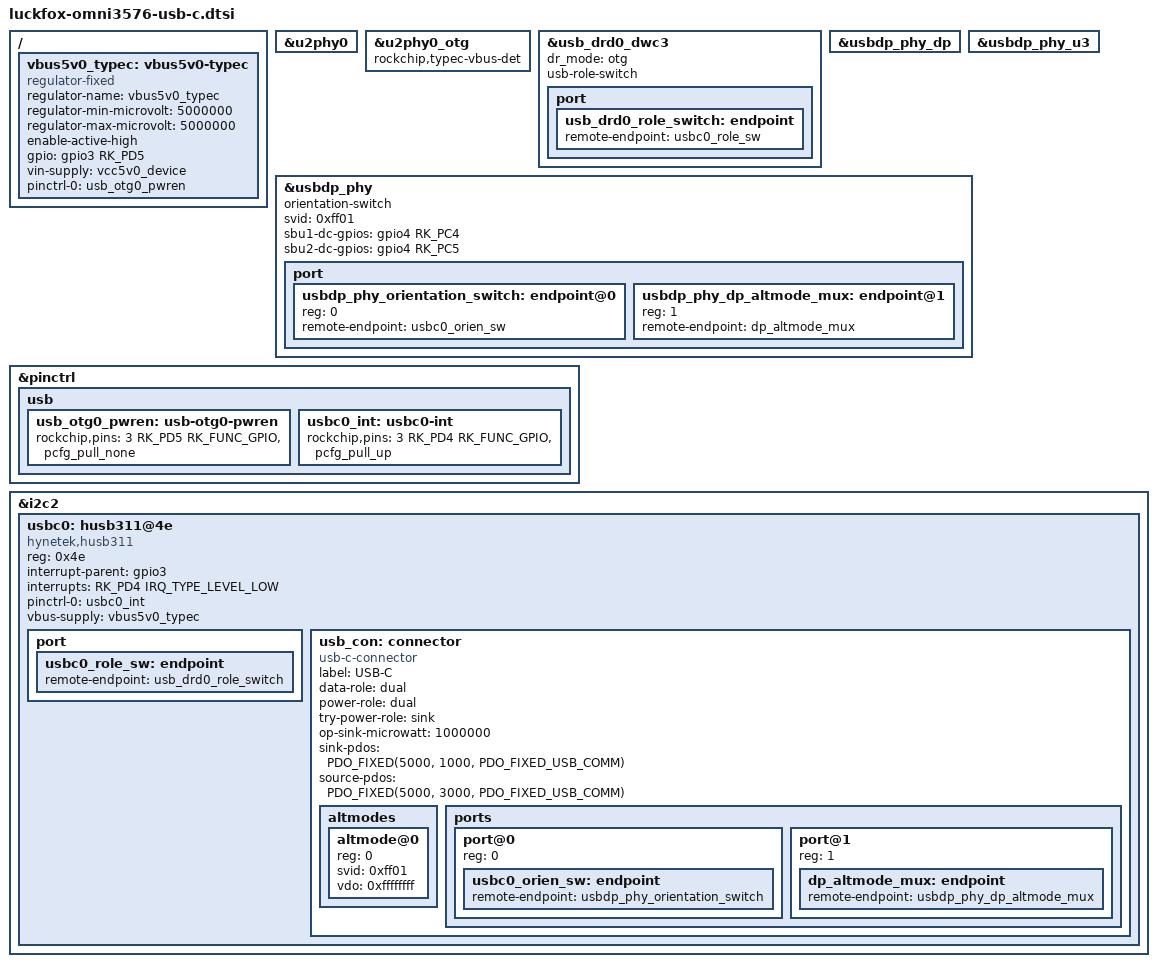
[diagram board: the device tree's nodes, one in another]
// SPDX-License-Identifier: (GPL-2.0+ OR MIT)
/*
 * Copyright (c) 2024 Luckfox Technology Co., Ltd.
 *
 */

#include <dt-bindings/usb/pd.h>
#include <dt-bindings/phy/phy.h>
// #include "luckfox-core3576.dtsi"
#include <dt-bindings/gpio/gpio.h>
#include <dt-bindings/display/rockchip_vop.h>

/ {
	vbus5v0_typec: vbus5v0-typec {
		compatible = "regulator-fixed";
		regulator-name = "vbus5v0_typec";
		regulator-min-microvolt = <5000000>;
		regulator-max-microvolt = <5000000>;
		enable-active-high;
		gpio = <&gpio3 RK_PD5 GPIO_ACTIVE_HIGH>;
		vin-supply = <&vcc5v0_device>;
		pinctrl-names = "default";
		pinctrl-0 = <&usb_otg0_pwren>;
	};
};

&u2phy0 {
	status = "okay";
};

&u2phy0_otg {
	rockchip,typec-vbus-det;
	status = "okay";
};

&usb_drd0_dwc3 {
	status = "okay";
	dr_mode = "otg";
	usb-role-switch;
	port {
		usb_drd0_role_switch: endpoint {
			remote-endpoint = <&usbc0_role_sw>;
		};
	};
};



&usbdp_phy_dp {
	status = "okay";
};
&usbdp_phy_u3 {
	status = "okay";
};
&usbdp_phy {
	status = "okay";
	orientation-switch;
	svid = <0xff01>;
	sbu1-dc-gpios = <&gpio4 RK_PC4 GPIO_ACTIVE_HIGH>;
	sbu2-dc-gpios = <&gpio4 RK_PC5 GPIO_ACTIVE_HIGH>;

	port {
		#address-cells = <1>;
		#size-cells = <0>;

		usbdp_phy_orientation_switch: endpoint@0 {
			reg = <0>;
			remote-endpoint = <&usbc0_orien_sw>;
		};

		usbdp_phy_dp_altmode_mux: endpoint@1 {
			reg = <1>;
			remote-endpoint = <&dp_altmode_mux>;
		};
	};
};


&pinctrl {
	usb {
		usb_otg0_pwren: usb-otg0-pwren {
			rockchip,pins = <3 RK_PD5 RK_FUNC_GPIO &pcfg_pull_none>;
		};

		usbc0_int: usbc0-int {
			rockchip,pins = <3 RK_PD4 RK_FUNC_GPIO &pcfg_pull_up>;
		};
	};

};


&i2c2 {
	status = "okay";

	usbc0: husb311@4e {
		compatible = "hynetek,husb311";
		reg = <0x4e>;
		interrupt-parent = <&gpio3>;
		interrupts = <RK_PD4 IRQ_TYPE_LEVEL_LOW>;
		pinctrl-names = "default";
		pinctrl-0 = <&usbc0_int>;
		vbus-supply = <&vbus5v0_typec>;
		status = "okay";

		port {
			usbc0_role_sw: endpoint {
				remote-endpoint = <&usb_drd0_role_switch>;
			};
		};

		usb_con: connector {
			compatible = "usb-c-connector";
			label = "USB-C";
			data-role = "dual";
			power-role = "dual";
			try-power-role = "sink";
			op-sink-microwatt = <1000000>;
			sink-pdos =
				<PDO_FIXED(5000, 1000, PDO_FIXED_USB_COMM)>;
			source-pdos =
				<PDO_FIXED(5000, 3000, PDO_FIXED_USB_COMM)>;

			altmodes {
				#address-cells = <1>;
				#size-cells = <0>;

				altmode@0 {
					reg = <0>;
					svid = <0xff01>;
					vdo = <0xffffffff>;
				};
			};

			ports {
				#address-cells = <1>;
				#size-cells = <0>;

				port@0 {
					reg = <0>;
					usbc0_orien_sw: endpoint {
						remote-endpoint = <&usbdp_phy_orientation_switch>;
					};
				};

				port@1 {
					reg = <1>;
					dp_altmode_mux: endpoint {
						remote-endpoint = <&usbdp_phy_dp_altmode_mux>;
					};
				};
			};
		};
	};
};
